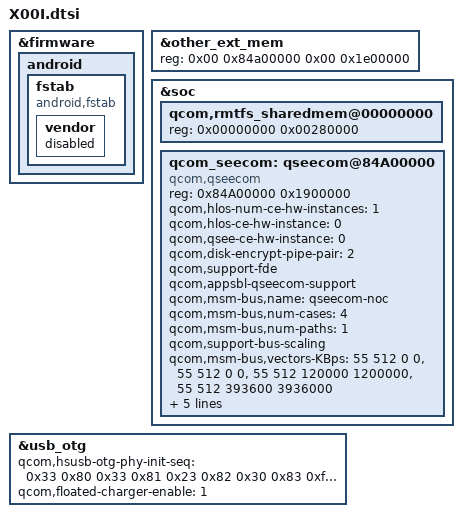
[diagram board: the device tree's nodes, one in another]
/*
 * Copyright (c) 2015-2018, The Linux Foundation. All rights reserved.
 *
 * This program is free software; you can redistribute it and/or modify
 * it under the terms of the GNU General Public License version 2 and
 * only version 2 as published by the Free Software Foundation.
 *
 * This program is distributed in the hope that it will be useful,
 * but WITHOUT ANY WARRANTY; without even the implied warranty of
 * MERCHANTABILITY or FITNESS FOR A PARTICULAR PURPOSE.  See the
 * GNU General Public License for more details.
 */

&firmware {
	android {
		fstab {
			compatible = "android,fstab";
			vendor {
				status = "disable";
			};
		};
	};
};

&other_ext_mem {
	reg = <0x00 0x84a00000 0x00 0x1e00000>;
};

&soc {
	qcom,rmtfs_sharedmem@00000000 {
		reg = <0x00000000 0x00280000>;
	};
};

&usb_otg {
	qcom,hsusb-otg-phy-init-seq = <0x33 0x80 0x33 0x81 0x23 0x82 0x30 0x83 0xffffffff>;
	qcom,floated-charger-enable = <1>;
};

&soc {
	/delete-node/ qseecom@85b00000;

	qcom_seecom: qseecom@84A00000 {
		compatible = "qcom,qseecom";
		reg = <0x84A00000 0x1900000>;
		reg-names = "secapp-region";
		qcom,hlos-num-ce-hw-instances = <1>;
		qcom,hlos-ce-hw-instance = <0>;
		qcom,qsee-ce-hw-instance = <0>;
		qcom,disk-encrypt-pipe-pair = <2>;
		qcom,support-fde;
		qcom,appsbl-qseecom-support;
		qcom,msm-bus,name = "qseecom-noc";
		qcom,msm-bus,num-cases = <4>;
		qcom,msm-bus,num-paths = <1>;
		qcom,support-bus-scaling;
		qcom,msm-bus,vectors-KBps =
			<55 512 0 0>,
			<55 512 0 0>,
			<55 512 120000 1200000>,
			<55 512 393600 3936000>;
		clocks = <&clock_gcc clk_crypto_clk_src>,
			 <&clock_gcc clk_gcc_crypto_clk>,
			 <&clock_gcc clk_gcc_crypto_ahb_clk>,
			 <&clock_gcc clk_gcc_crypto_axi_clk>;
		clock-names = "core_clk_src", "core_clk",
				"iface_clk", "bus_clk";
		qcom,ce-opp-freq = <100000000>;
	};
};
